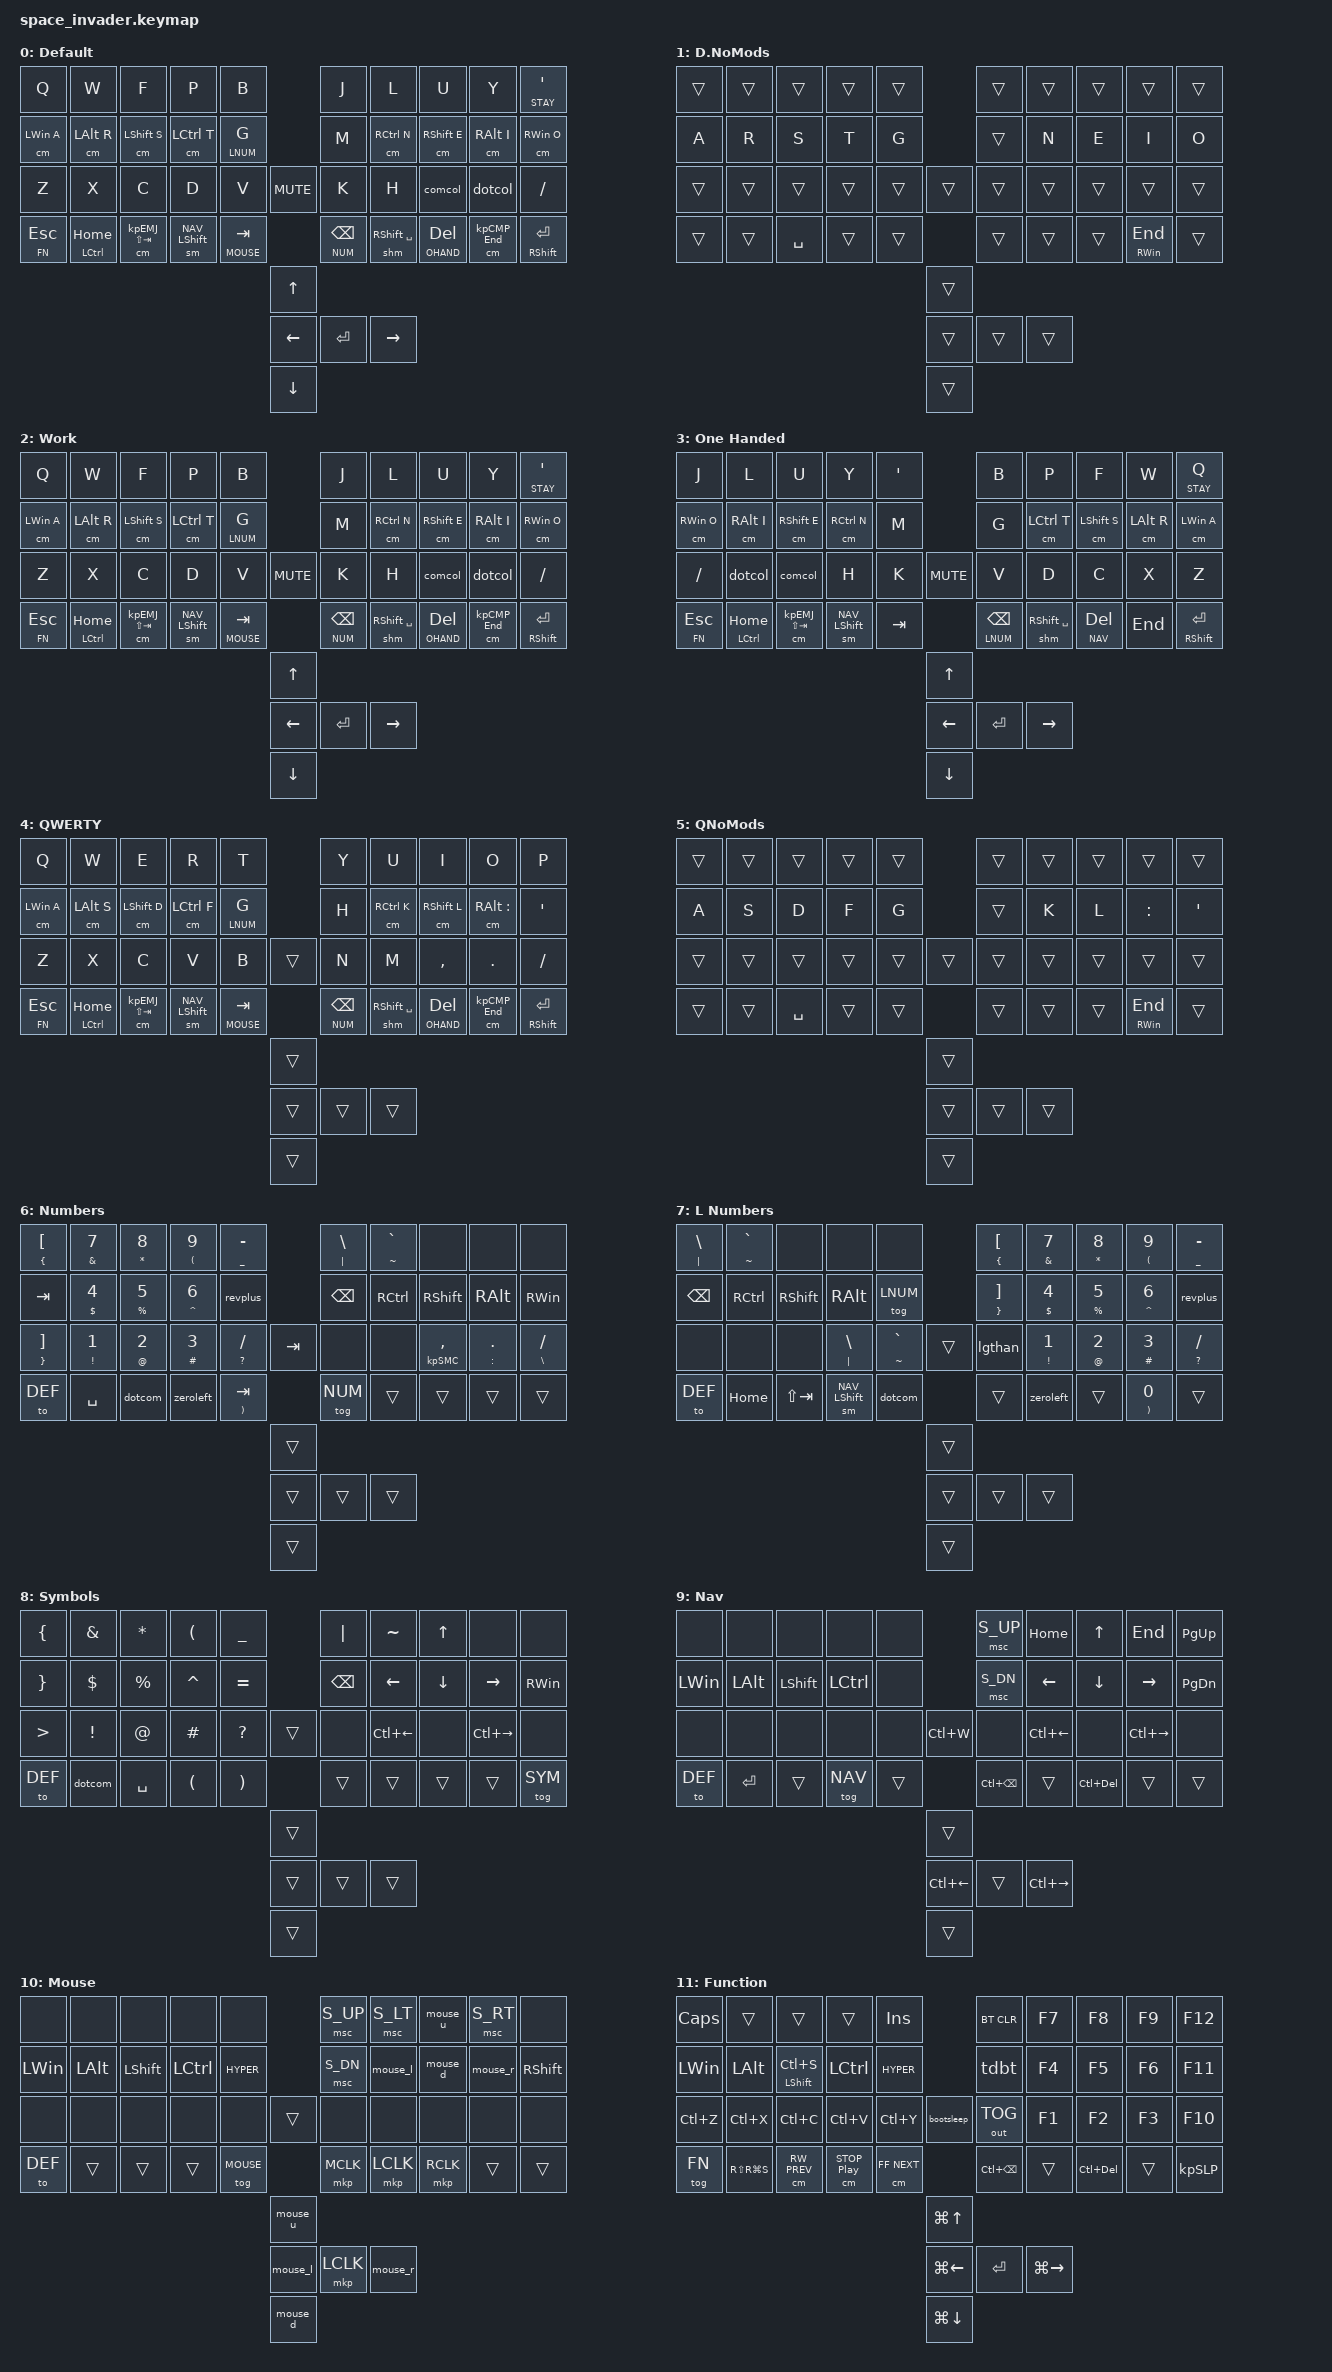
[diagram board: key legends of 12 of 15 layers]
/*
 * Copyright (c) 2021 Tom Butcher
 *
 * SPDX-License-Identifier: MIT
 */

 // standard build command: west build -b adafruit_feather_nrf52840 -- -DSHIELD=space_invader

 /* ********* TO DO *************
	* Once unicode works, create macros that change the layer and send the appropriate F key
	  (for helper image) at the same time.
 */

#include <behaviors.dtsi>
#include <dt-bindings/zmk/keys.h>
#include <dt-bindings/zmk/bt.h>
#include <dt-bindings/zmk/outputs.h>
#include <dt-bindings/zmk/ext_power.h>

// Layer Defs
#define DEF		0
#define DEF_NM	1
#define WORK	2
#define OHAND	3
#define QWERTY	4
#define QWER_NM	5
#define NUM		6
#define LNUM	7
#define SYM		8
#define NAV		9
#define MOUSE	10	
#define FN		11	// Reserved for future use 
#define EMOJI	12	// Reserved for future use
#define CMP		13
#define STAY	14

// F Key subs (use with AHK)
#define KP_PLS	(F18)
#define KP_COM	(F19)
#define KP_SMC	(F20)
#define KP_EMJ	(F21)
#define KP_CMP	(F23)
#define KP_SLP	(LG(LA(LS(LC(APOS)))))

// Other defs
#define xxx		&none	
#define ___		&trans
#define HYPER	(LG(LA(LS(LCTRL))))		  // If I want to send a hypered key, then I might need to make a custom behavior
// #define HYPER	(LG(LA(LS(LCTRL))))   // Maybe try to make a custom mod kp?

#include <../boards/shields/space_invader/key_positions.h>
#include <../boards/shields/space_invader/mouse.dtsi>
#include <../boards/shields/space_invader/helper.h>
#include <../boards/shields/space_invader/behaviors.dtsi>
#include <../boards/shields/space_invader/combos.dtsi>
#include <../boards/shields/space_invader/private.dtsi>

&mt { quick_tap_ms = <200>; };
&lt { quick_tap_ms = <200>; };

/ {
	conditional_layers {
        compatible = "zmk,conditional-layers";
        tri_layer {
            if-layers = <1 4>;
            then-layer = <5>;
        };
    };

	// behaviors {
	// 	tdbt: tap_dance_bluetooth {
	// 	compatible = "zmk,behavior-tap-dance";
    //     #binding-cells = <0>;
	// 	tapping-term-ms = <200>;
	//     bindings = <&bt BT_SEL 0>, <&bt BT_SEL 1>, <&bt BT_SEL 2>, <&bt BT_SEL 3>, <&bt BT_SEL 4>;
	// 	};
	// };

	keymap {
		compatible = "zmk,keymap";

							// -------------------------------------------------TEMPLATE-------------------------------------------------
							// |      |      |      |      |      |                                  |      |      |      |      |      |
							// |      |      |      |      |      |                                  |      |      |      |      |      |
							// |      |      |      |      |      |             |      |             |      |      |      |      |      |
							// |      |------|      |      |      |      |      	          |      |      |      |      |------|      |
							// |----------------------------------|      |      |      |      |      |----------------------------------|
							// ----------------------------------------------------------------------------------------------------------

//------------------------------------------------------------------------------EMPTY TEMPLATE-----------------------------------------------------------------------------
//╭─────────────┬─────────────┬─────────────┬─────────────┬─────────────╮	 		  			    ╭─────────────┬─────────────┬─────────────┬─────────────┬─────────────╮

//├─────────────┼─────────────┼─────────────┼─────────────┼─────────────┤	 					    ├─────────────┼─────────────┼─────────────┼─────────────┼─────────────┤

//├─────────────┼─────────────┼─────────────┼─────────────┼─────────────┤	   ╭─────────────╮      ├─────────────┼─────────────┼─────────────┼─────────────┼─────────────┤

//├─────────────┴───┬─────────┼─────────────┼─────────────┼─────────────┼──────╰──────╮──────╯──────┼─────────────┼─────────────┼─────────────┼─────────┬───┴─────────────┤

//╰─────────────────╯		  ╰─────────────┴─────────────┴─────────────┴─────────────╯─────────────┴─────────────┴─────────────┴─────────────╯	   		╰─────────────────╯
//																		  		 ╭─────────╮

//																	   ╭─────────┼─────────┼─────────╮

//																	   ╰─────────┼─────────┼─────────╯

//																				 ╰─────────╯



		default_layer { 
			display-name = "Default";
			// -------------------------------------------------COLEMAK--------------------------------------------------
			// |  Q   |  W   |  F   |  P   |  B   |                                  |  J   |  L   |  U   |  Y   |  '"  |
			// |  A   |  R   |  S   |  T   |  G   |                                  |  M   |  N   |  E   |  I   |  O   |
			// |  Z   |  X   |  C   |  D   |  V   |             | Mute |             |  K   |  H   |  ,;  |  .:  |  /?  |  // In the future, maybe change back to interobang
			// |  Esc |------| Home |ShftTb|StckSh| Tab  |      	          | Bspc | Space| Del  |  End |------|  Del |  // Although maybe slash is more common than exclamation mark?
			// |----------------------------------|  Up  | Left | Enter| Right| Down |----------------------------------|
			// ----------------------------------------------------------------------------------------------------------
			// ------------------------------------------------HOLD LAYER------------------------------------------------
			// |      |      |      |      |      |                                  |      |      |      |      | Stay |
			// | LWin | LAlt | LShft| LCtrl| LNum |                                  |      | RCtrl| RShft| RAlt | RWin |
			// |      |      |      |      |      |             |      |             |      |      |      |      |      |
			// |  Fn  |------| LCtrl| Emoji| Nav  | Mouse|      	          | Num  | RShft| Cmp  | Sym  |------| Media|
			// |----------------------------------|      |      |      |      |      |----------------------------------|
			// ----------------------------------------------------------------------------------------------------------

			bindings = <
//--------------------------------------------------------------------------------COLEMAK---------------------------------------------------------------------------------
//╭─────────────┬─────────────┬─────────────┬─────────────┬─────────────╮	 		  			    ╭─────────────┬─────────────┬─────────────┬─────────────┬─────────────╮
  	&kp Q		  &kp W			&kp F		  &kp P			&kp B									  &kp J			&kp L		  &kp U			&kp Y		  &lt STAY APOS		// &tdq
//├─────────────┼─────────────┼─────────────┼─────────────┼─────────────┤	 					    ├─────────────┼─────────────┼─────────────┼─────────────┼─────────────┤
  	&cm LWIN A	  &cm LALT R	&cm LSHFT S	  &cm LCTRL T	&lt LNUM G								  &kp M			&cm RCTRL N	  &cm RSHFT E	&cm RALT I	  &cm RWIN O
//├─────────────┼─────────────┼─────────────┼─────────────┼─────────────┤	   ╭─────────────╮      ├─────────────┼─────────────┼─────────────┼─────────────┼─────────────┤
	&kp Z		  &kp X			&kp C		  &kp D			&kp V				  &kp C_MUTE		  &kp K			&kp H		  &comcol		&dotcol		  &kp SLASH
//├─────────────┴───┬─────────┼─────────────┼─────────────┼─────────────┬──────╰──────╮──────╯──────┬─────────────┼─────────────┼─────────────┴─────────┬───┴─────────────┤
	&lt FN ESC			  &mt LCTRL HOME &cm KP_EMJ LS(TAB) &sm NAV LSHFT &lt MOUSE TAB	&lt NUM BSPC &shm RSHFT SPACE &lt OHAND DEL &cm KP_CMP END		  &mt RSHFT RET
//╰─────────────────╯		  ╰─────────────┴─────────────┴─────────────┴─────────────╯─────────────┴─────────────┴─────────────┴─────────────╯	   		╰─────────────────╯
//																		  		 ╭─────────╮
																				  &kp UP
//																	   ╭─────────┼─────────┼─────────╮
																		&kp LEFT  &kp RET	&kp RIGHT
//																	   ╰─────────┼─────────┼─────────╯
																				  &kp DOWN
//																				 ╰─────────╯
			>;

			sensor-bindings = <&scroll>;
		};

		default_no_mods_layer { // Just turns off homerow mods, so no need for the whole keymap diagram
			display-name = "D.NoMods";
			bindings = <___ ___	___ ___ ___ ___ ___ ___ ___ ___ &kp A &kp R &kp S &kp T &kp G ___ &kp N &kp E &kp I &kp O ___ ___ ___ ___ ___ ___ ___ ___ ___ ___ ___
						___ ___ &kp SPACE ___ ___ ___ ___ ___ &mt RWIN END ___ ___ ___ ___ ___ ___>;
			sensor-bindings = <&scroll>;
		};

		work_layer { 
			display-name = "Work";
			bindings = <
//--------------------------------------------------------------------------------COLEMAK---------------------------------------------------------------------------------
//╭─────────────┬─────────────┬─────────────┬─────────────┬─────────────╮	 		  			    ╭─────────────┬─────────────┬─────────────┬─────────────┬─────────────╮
  	&kp Q		  &kp W			&kp F		  &kp P			&kp B									  &kp J			&kp L		  &kp U			&kp Y		  &lt STAY APOS		// &tdq
//├─────────────┼─────────────┼─────────────┼─────────────┼─────────────┤	 					    ├─────────────┼─────────────┼─────────────┼─────────────┼─────────────┤
  	&cm LWIN A	  &cm LALT R	&cm LSHFT S	  &cm LCTRL T	&lt LNUM G								  &kp M			&cm RCTRL N	  &cm RSHFT E	&cm RALT I	  &cm RWIN O
//├─────────────┼─────────────┼─────────────┼─────────────┼─────────────┤	   ╭─────────────╮      ├─────────────┼─────────────┼─────────────┼─────────────┼─────────────┤
	&kp Z		  &kp X			&kp C		  &kp D			&kp V				  &kp C_MUTE		  &kp K			&kp H		  &comcol		&dotcol		  &kp SLASH
//├─────────────┴───┬─────────┼─────────────┼─────────────┼─────────────┬──────╰──────╮──────╯──────┬─────────────┼─────────────┼─────────────┴─────────┬───┴─────────────┤
	&lt FN ESC			  &mt LCTRL HOME &cm KP_EMJ LS(TAB) &sm NAV LSHFT &lt MOUSE TAB	&lt NUM BSPC &shm RSHFT SPACE &lt OHAND DEL &cm KP_CMP END		  &mt RSHFT RET
//╰─────────────────╯		  ╰─────────────┴─────────────┴─────────────┴─────────────╯─────────────┴─────────────┴─────────────┴─────────────╯	   		╰─────────────────╯
//																		  		 ╭─────────╮
																				  &kp UP
//																	   ╭─────────┼─────────┼─────────╮
																		&kp LEFT  &kp RET	&kp RIGHT
//																	   ╰─────────┼─────────┼─────────╯
																				  &kp DOWN
//																				 ╰─────────╯
			>;

			sensor-bindings = <&scroll>;
		};

		one_hand_layer { 
			display-name = "One Handed";
			bindings = <
//--------------------------------------------------------------------------------ONE HAND---------------------------------------------------------------------------------
//╭─────────────┬─────────────┬─────────────┬─────────────┬─────────────╮	 		  			    ╭─────────────┬─────────────┬─────────────┬─────────────┬─────────────╮
  	&kp J		  &kp L			&kp U		  &kp Y			&kp APOS								  &kp B			&kp P		  &kp F			&kp W		  &lt STAY Q
//├─────────────┼─────────────┼─────────────┼─────────────┼─────────────┤	 					    ├─────────────┼─────────────┼─────────────┼─────────────┼─────────────┤
  	&cm RWIN O	  &cm RALT I	&cm RSHFT E	  &cm RCTRL N	&kp M									  &kp G			&cm LCTRL T	  &cm LSHFT S	&cm LALT R	  &cm LWIN A
//├─────────────┼─────────────┼─────────────┼─────────────┼─────────────┤	   ╭─────────────╮      ├─────────────┼─────────────┼─────────────┼─────────────┼─────────────┤
	&kp SLASH	  &dotcol		&comcol		  &kp H		    &kp K				 &kp C_MUTE			  &kp V			&kp D		  &kp C			&kp X		  &kp Z
//├─────────────┴───┬─────────┼─────────────┼─────────────┼─────────────┬──────╰──────╮──────╯──────┬─────────────┼─────────────┼─────────────┴─────────┬───┴─────────────┤
	&lt FN ESC			  &mt LCTRL HOME &cm KP_EMJ LS(TAB) &sm NAV LSHFT &kp TAB		&lt LNUM BSPC &shm RSHFT SPACE &lt NAV DEL &kp END					&mt RSHFT RET
//╰─────────────────╯		  ╰─────────────┴─────────────┴─────────────┴─────────────╯─────────────┴─────────────┴─────────────┴─────────────╯	   		╰─────────────────╯
//																		  		 ╭─────────╮
																				  &kp UP
//																	   ╭─────────┼─────────┼─────────╮
																		&kp LEFT  &kp RET	&kp RIGHT
//																	   ╰─────────┼─────────┼─────────╯
																				  &kp DOWN
//																				 ╰─────────╯
			>;

			sensor-bindings = <&scroll>;
		};

		qwerty_layer {
			display-name = "QWERTY";
			bindings = <
//---------------------------------------------------------------------------------QWERTY---------------------------------------------------------------------------------
//╭─────────────┬─────────────┬─────────────┬─────────────┬─────────────╮	 		  			    ╭─────────────┬─────────────┬─────────────┬─────────────┬─────────────╮
	&kp Q		  &kp W			&kp E		  &kp R			&kp T									  &kp Y			&kp U		  &kp I			&kp O		  &kp P 		// &lt STAY APOS
//├─────────────┼─────────────┼─────────────┼─────────────┼─────────────┤	 					    ├─────────────┼─────────────┼─────────────┼─────────────┼─────────────┤
	&cm LWIN A	  &cm LALT S	&cm LSHFT D	  &cm LCTRL F	&lt LNUM G								  &kp H			&cm RCTRL K	  &cm RSHFT L	&cm RALT COLON &kp APOS
//├─────────────┼─────────────┼─────────────┼─────────────┼─────────────┤	   ╭─────────────╮      ├─────────────┼─────────────┼─────────────┼─────────────┼─────────────┤
	&kp Z		  &kp X			&kp C		  &kp V			&kp B				 ___				  &kp N			&kp M		  &kp COMMA		&kp DOT		  &kp SLASH
//├─────────────┴───┬─────────┼─────────────┼─────────────┼─────────────┬──────╰──────╮──────╯──────┬─────────────┼─────────────┼─────────────┴─────────┬───┴─────────────┤
	&lt FN ESC			  &mt LCTRL HOME &cm KP_EMJ LS(TAB) &sm NAV LSHFT &lt MOUSE TAB	&lt NUM BSPC &shm RSHFT SPACE &lt OHAND DEL &cm KP_CMP END		  &mt RSHFT RET
//╰─────────────────╯		  ╰─────────────┴─────────────┴─────────────┴─────────────╯─────────────┴─────────────┴─────────────┴─────────────╯	   		╰─────────────────╯
//																		  		 ╭─────────╮
																				   ___	
//																	   ╭─────────┼─────────┼─────────╮
																		 ___	   ___		 ___	
//																	   ╰─────────┼─────────┼─────────╯
																				   ___	
//																				 ╰─────────╯
			>;

			sensor-bindings = <&scroll>;
		};

		qwerty_no_mods_layer { // Just turns off homerow mods, so no need for the whole keymap diagram
			display-name = "QNoMods";
			bindings = <___ ___	___ ___ ___ ___ ___ ___ ___ ___ &kp A &kp S &kp D &kp F &kp G ___ &kp K &kp L &kp COLON &kp APOS ___ ___ ___ ___ ___ ___ ___ ___ ___ ___ ___
						___ ___ &kp SPACE ___ ___ ___ ___ ___ &mt RWIN END ___ ___ ___ ___ ___ ___>;
			sensor-bindings = <&scroll>;
		};

		number_layer {
			display-name = "Numbers";
			
			// --------------------------------------------------NUMBER--------------------------------------------------
			// |  [{  |  1!  |  2@  |  3#  |  -_  |                                  |      |  \|  |  `~  |      |      |
			// |  ]}  |  4$  |  5%  |  6^  |  =+  |                                  | BSPC | RCTRL| RSHFT| RALT | RWIN |
			// |  <>  |  7&  |  8*  |  9(  |  \|  |             |      |             |      |      |  ,;  |  .:  |      |
			// | DEF |------| SPACE|  .,  |  0(  |  0)  |      	          |      |      |      |      |------|      |
			// |----------------------------------|      |      |      |      |      |----------------------------------|
			// ----------------------------------------------------------------------------------------------------------

			bindings = < // All numbers use auto-shift for symbols
//---------------------------------------------------------------------------------NUMBERS---------------------------------------------------------------------------------
//╭─────────────┬─────────────┬─────────────┬─────────────┬─────────────╮	 		  				╭─────────────┬─────────────┬─────────────┬─────────────┬─────────────╮
	&as LBRC LBKT &as AMPS N7	&as ASTRK N8  &as LPAR N9 	&as UNDER MINUS							  &as PIPE BSLH &as TILDE GRAVE xxx		  	xxx			  xxx
//├─────────────┼─────────────┼─────────────┼─────────────┼─────────────┤	 						├─────────────┼─────────────┼─────────────┼─────────────┼─────────────┤
	&kp TAB		  &as DLLR N4	&as PRCNT N5  &as CARET N6	&revplus								  &kp BSPC		&kp RCTRL	  &kp RSHFT		&kp RALT	  &kp RWIN
//├─────────────┼─────────────┼─────────────┼─────────────┼─────────────┤	   ╭─────────────╮		├─────────────┼─────────────┼─────────────┼─────────────┼─────────────┤
	&as RBRC RBKT &as EXCL N1	&as AT N2	  &as HASH N3	&as QMARK SLASH	  	 &kp TAB	   		  xxx			xxx		   &as KP_SMC COMMA &as COLON DOT &as BSLH SLASH
//├─────────────┴───┬─────────┼─────────────┼─────────────┼─────────────┬──────╰──────╮──────╯──────┬─────────────┼─────────────┼─────────────┴─────────┬───┴─────────────┤
	&to DEF						&kp SPACE	  &dotcom		&zeroleft	  &as RPAR TAB	&tog NUM	  ___		 	___			  ___						  ___	
//╰─────────────────╯		  ╰─────────────┴─────────────┴─────────────┴─────────────╯─────────────┴─────────────┴─────────────┴─────────────╯	   		╰─────────────────╯
//																		  		 ╭─────────╮
																				   ___	
//																	   ╭─────────┼─────────┼─────────╮
																		 ___	   ___		 ___	
//																	   ╰─────────┼─────────┼─────────╯
																				   ___	
//																				 ╰─────────╯
			>;

			sensor-bindings = <&volume>;
		};


		left_number_layer {
			display-name = "L Numbers";
			
			// -----------------------------------------------LEFT NUMBER------------------------------------------------
			// |  [{  |  1!  |  2@  |  3#  |  -_  |                                  |      |  \|  |  `~  |      |      |
			// |  ]}  |  4$  |  5%  |  6^  |  =+  |                                  | BSPC | RCTRL| RSHFT| RALT | RWIN |
			// |  <>  |  7&  |  8*  |  9(  |  \|  |             |      |             |      |      |  ,;  |  .:  |      |
			// | DEF |------| SPACE|  .,  |  0(  |  0)  |      	          |      |      |      |      |------|      |
			// |----------------------------------|      |      |      |      |      |----------------------------------|
			// ----------------------------------------------------------------------------------------------------------

			bindings = < // All numbers use auto-shift for symbols
//------------------------------------------------------------------------------LEFT NUMBERS-------------------------------------------------------------------------------
//╭─────────────┬─────────────┬─────────────┬─────────────┬─────────────╮	 		  				╭─────────────┬─────────────┬─────────────┬─────────────┬─────────────╮
	&as PIPE BSLH &as TILDE GRAVE xxx		  xxx			xxx										  &as LBRC LBKT &as AMPS N7	  &as ASTRK N8  &as LPAR N9	  &as UNDER MINUS
//├─────────────┼─────────────┼─────────────┼─────────────┼─────────────┤	 						├─────────────┼─────────────┼─────────────┼─────────────┼─────────────┤
	&kp BSPC	  &kp RCTRL	  	&kp RSHFT	  &kp RALT		&tog LNUM								  &as RBRC RBKT &as DLLR N4	  &as PRCNT N5  &as CARET N6  &revplus
//├─────────────┼─────────────┼─────────────┼─────────────┼─────────────┤	   ╭─────────────╮		├─────────────┼─────────────┼─────────────┼─────────────┼─────────────┤
	 xxx		  xxx			xxx			  &as PIPE BSLH &as TILDE GRAVE		  ___				  &lgthan		&as EXCL N1	  &as AT N2		&as HASH N3	  &as QMARK SLASH
//├─────────────┴───┬─────────┼─────────────┼─────────────┼─────────────┬──────╰──────╮──────╯──────┬─────────────┼─────────────┼─────────────┴─────────┬───┴─────────────┤
	&to DEF						&kp HOME	  &kp LS(TAB)	&sm NAV LSHFT &dotcom		___			  &zeroleft	  	___			  &as RPAR N0			  	  ___	
//╰─────────────────╯		  ╰─────────────┴─────────────┴─────────────┴─────────────╯─────────────┴─────────────┴─────────────┴─────────────╯	   		╰─────────────────╯
//																		  		 ╭─────────╮
																				   ___	
//																	   ╭─────────┼─────────┼─────────╮
																		 ___	   ___		 ___	
//																	   ╰─────────┼─────────┼─────────╯
																				   ___	
//																				 ╰─────────╯
			>;

			sensor-bindings = <&volume>;
		};

		symbol_layer {
			display-name = "Symbols";
			bindings = <
//---------------------------------------------------------------------------------SYMBOLS--------------------------------------------------------------------------------
//╭─────────────┬─────────────┬─────────────┬─────────────┬─────────────╮	 		  			    ╭─────────────┬─────────────┬─────────────┬─────────────┬─────────────╮
	&kp LBRC	  &kp AMPS		&kp ASTRK	  &kp LPAR		&kp UNDER					     		  &kp PIPE		&kp TILDE	  &kp UP			xxx			  xxx	
//├─────────────┼─────────────┼─────────────┼─────────────┼─────────────┤	 					    ├─────────────┼─────────────┼─────────────┼─────────────┼─────────────┤
	&kp RBRC	  &kp DLLR		&kp PRCNT	  &kp CARET		&kp EQUAL								  &kp BSPC		&kp LEFT	  &kp DOWN    	&kp RIGHT	  &kp RWIN
//├─────────────┼─────────────┼─────────────┼─────────────┼─────────────┤	   ╭─────────────╮      ├─────────────┼─────────────┼─────────────┼─────────────┼─────────────┤
	&kp GT		  &kp EXCL		&kp AT		  &kp HASH		&kp QMARK		  	 ___				  xxx			&kp LC(LEFT)  xxx			&kp LC(RIGHT)  xxx	
//├─────────────┴───┬─────────┼─────────────┼─────────────┼─────────────┬──────╰──────╮──────╯──────┬─────────────┼─────────────┼─────────────┴─────────┬───┴─────────────┤
	&to DEF						&dotcom		  &kp SPACE		&kp LPAR	  &kp RPAR	    ___			  ___			___			  ___						  &tog SYM
//╰─────────────────╯		  ╰─────────────┴─────────────┴─────────────┴─────────────╯─────────────┴─────────────┴─────────────┴─────────────╯	   		╰─────────────────╯
//																		  		 ╭─────────╮
																				   ___	
//																	   ╭─────────┼─────────┼─────────╮
																		 ___	   ___		 ___	
//																	   ╰─────────┼─────────┼─────────╯
																				   ___	
//																				 ╰─────────╯
			>;

			sensor-bindings = <&volume>;
		};

		navigation_layer {
			display-name = "Nav";
			bindings = <
//-------------------------------------------------------------------------------NAVIGATION-------------------------------------------------------------------------------
//╭─────────────┬─────────────┬─────────────┬─────────────┬─────────────╮	 		  			    ╭─────────────┬─────────────┬─────────────┬─────────────┬─────────────╮
	xxx			  xxx			xxx			  xxx			xxx										  &msc S_UP   	&kp HOME	  &kp UP		&kp END		  &kp PG_UP
//├─────────────┼─────────────┼─────────────┼─────────────┼─────────────┤	 					    ├─────────────┼─────────────┼─────────────┼─────────────┼─────────────┤
  	&kp LWIN	  &kp LALT	 	&kp LSHFT	  &kp LCTRL		xxx										  &msc S_DN   	&kp LEFT	  &kp DOWN    	&kp RIGHT 	  &kp PG_DN
//├─────────────┼─────────────┼─────────────┼─────────────┼─────────────┤	   ╭─────────────╮      ├─────────────┼─────────────┼─────────────┼─────────────┼─────────────┤
	xxx			  xxx			xxx			  xxx			xxx				     &kp LC(W)			  xxx			&kp LC(LEFT)  xxx			&kp LC(RIGHT) xxx	
//├─────────────┴───┬─────────┼─────────────┼─────────────┼─────────────┬──────╰──────╮──────╯──────┬─────────────┼─────────────┼─────────────┴─────────┬───┴─────────────┤
	&to DEF						&kp RET		  ___			&tog NAV	  ___		  	&kp LC(BSPC)  ___			&kp LC(DEL)	  ___						  ___	
//╰─────────────────╯		  ╰─────────────┴─────────────┴─────────────┴─────────────╯─────────────┴─────────────┴─────────────┴─────────────╯	   		╰─────────────────╯
//																		  		 ╭─────────╮
																				   ___	
//																	   ╭─────────┼─────────┼─────────╮
																	&kp LC(LEFT)   ___		 &kp LC(RIGHT)
//																	   ╰─────────┼─────────┼─────────╯
																				   ___	
//																				 ╰─────────╯
			>;

			sensor-bindings = <&tabs>;	// Scroll tabs
		};

		mouse_layer {
			display-name = "Mouse";
			bindings = <
//----------------------------------------------------------------------------------MOUSE---------------------------------------------------------------------------------
//╭─────────────┬─────────────┬─────────────┬─────────────┬─────────────╮	 		  			    ╭─────────────┬─────────────┬─────────────┬─────────────┬─────────────╮
	xxx			  xxx			xxx			  xxx			xxx										  &msc S_UP		&msc S_LT	  &mouse_u		&msc S_RT 	  xxx	
//├─────────────┼─────────────┼─────────────┼─────────────┼─────────────┤	 					    ├─────────────┼─────────────┼─────────────┼─────────────┼─────────────┤
	&kp LWIN	  &kp LALT		&kp LSHFT	  &kp LCTRL		&kp HYPER								  &msc S_DN		&mouse_l	  &mouse_d		&mouse_r	  &kp RSHFT	
//├─────────────┼─────────────┼─────────────┼─────────────┼─────────────┤	   ╭─────────────╮      ├─────────────┼─────────────┼─────────────┼─────────────┼─────────────┤
	xxx			  xxx			xxx			  xxx			xxx					 ___				  xxx			xxx			  xxx			xxx			  xxx
//├─────────────┴───┬─────────┼─────────────┼─────────────┼─────────────┬──────╰──────╮──────╯──────┬─────────────┼─────────────┼─────────────┴─────────┬───┴─────────────┤
	&to DEF						___			  ___			___			  &tog MOUSE	&mkp MCLK	  &mkp LCLK		&mkp RCLK	  ___						  ___	
//╰─────────────────╯		  ╰─────────────┴─────────────┴─────────────┴─────────────╯─────────────┴─────────────┴─────────────┴─────────────╯	   		╰─────────────────╯
//																		  		 ╭─────────╮
																				   &mouse_u	
//																	   ╭─────────┼─────────┼─────────╮
																		 &mouse_l  &mkp LCLK &mouse_r	
//																	   ╰─────────┼─────────┼─────────╯
																				   &mouse_d	
//																				 ╰─────────╯
			>;

			sensor-bindings = <&scroll>;
		};

		function_layer {
			display-name = "Function";
			bindings = <
//--------------------------------------------------------------------------------FUNCTION--------------------------------------------------------------------------------
//╭─────────────┬─────────────┬─────────────┬─────────────┬─────────────╮	 		  			    ╭─────────────┬─────────────┬─────────────┬─────────────┬─────────────╮
	&kp CAPS	  ___	 		___			  ___			&kp INS									  &bt BT_CLR	&kp F7		  &kp F8		&kp F9		  &kp F12
//├─────────────┼─────────────┼─────────────┼─────────────┼─────────────┤	 						├─────────────┼─────────────┼─────────────┼─────────────┼─────────────┤
	&kp LWIN	  &kp LALT	 &mt LSHFT LC(S)  &kp LCTRL		&kp HYPER								  &tdbt			&kp F4		  &kp F5		&kp F6		  &kp F11
//├─────────────┼─────────────┼─────────────┼─────────────┼─────────────┤	   ╭─────────────╮      ├─────────────┼─────────────┼─────────────┼─────────────┼─────────────┤
	&kp LC(Z)	  &kp LC(X)		&kp LC(C)	  &kp LC(V)		&kp LC(Y)   		 &bootsleep			  &out OUT_TOG	&kp F1		  &kp F2		&kp F3		  &kp F10
//├─────────────┴───┬─────────┼─────────────┼─────────────┼─────────────┬──────╰──────╮──────╯──────┬─────────────┼─────────────┼─────────────┴─────────┬───┴─────────────┤
	&tog FN					  &kp RS(RG(S)) &cm C_RW C_PREV &cm C_STOP C_PP &cm C_FF C_NEXT &kp LC(BSPC) ___		&kp LC(DEL)	  ___						  &kp KP_SLP	
//╰─────────────────╯		  ╰─────────────┴─────────────┴─────────────┴─────────────╯─────────────┴─────────────┴─────────────┴─────────────╯	   		╰─────────────────╯
//																		  		 ╭─────────╮
																				   &kp LG(UP)
//																	   ╭─────────┼─────────┼─────────╮
																	  &kp LG(LEFT) &kp RET	 &kp LG(RIGHT)
//																	   ╰─────────┼─────────┼─────────╯
																				   &kp LG(DOWN)
//																				 ╰─────────╯
			>;

			sensor-bindings = <&volume>;
		};

		emoji_layer { // todo: Unicode (including emoji) not yet implemented in ZMK. Maybe try using AHK in the meantime?
			display-name = "Emoji";
			bindings = <
//----------------------------------------------------------------------------------EMOJI---------------------------------------------------------------------------------
//╭─────────────┬─────────────┬─────────────┬─────────────┬─────────────╮	 		  			    ╭─────────────┬─────────────┬─────────────┬─────────────┬─────────────╮
	&kp Q		  ___			___			  ___			___										  ___			___			  ___			___			  ___	
//├─────────────┼─────────────┼─────────────┼─────────────┼─────────────┤	 					    ├─────────────┼─────────────┼─────────────┼─────────────┼─────────────┤
	___			  ___			___			  ___			___										  ___			___			  ___			___			  ___	
//├─────────────┼─────────────┼─────────────┼─────────────┼─────────────┤	   ╭─────────────╮      ├─────────────┼─────────────┼─────────────┼─────────────┼─────────────┤
	___			  ___			___			  ___			___					 ___				  ___			___			  ___			___			  ___	
//├─────────────┴───┬─────────┼─────────────┼─────────────┼─────────────┬──────╰──────╮──────╯──────┬─────────────┼─────────────┼─────────────┴─────────┬───┴─────────────┤
	&to DEF		  				___			  &tog EMOJI	___			  ___			___			  ___			___			  ___						  ___	
//╰─────────────────╯		  ╰─────────────┴─────────────┴─────────────┴─────────────╯─────────────┴─────────────┴─────────────┴─────────────╯	   		╰─────────────────╯
//																		  		 ╭─────────╮
																				   ___	
//																	   ╭─────────┼─────────┼─────────╮
																		 ___	   ___		 ___	
//																	   ╰─────────┼─────────┼─────────╯
																				   ___	
//																				 ╰─────────╯
			>;

			sensor-bindings = <&scroll>;
		};

		compose_layer { // todo: unicode not yet implemented in ZMK. Maybe try using AHK in the meantime?
			display-name = "Compose";
			bindings = <
//---------------------------------------------------------------------------------COMPOSE--------------------------------------------------------------------------------
//╭─────────────┬─────────────┬─────────────┬─────────────┬─────────────╮	 		  			    ╭─────────────┬─────────────┬─────────────┬─────────────┬─────────────╮
	&kp Q		  ___			___			  ___			___										  ___			___			  ___			___			  ___	
//├─────────────┼─────────────┼─────────────┼─────────────┼─────────────┤	 					    ├─────────────┼─────────────┼─────────────┼─────────────┼─────────────┤
	___			  ___			___			  ___			___										  ___			___			  ___			___			  ___	
//├─────────────┼─────────────┼─────────────┼─────────────┼─────────────┤	   ╭─────────────╮      ├─────────────┼─────────────┼─────────────┼─────────────┼─────────────┤
	___			  ___			___			  ___			___					 ___				  ___			___			  ___			___			  ___	
//├─────────────┴───┬─────────┼─────────────┼─────────────┼─────────────┬──────╰──────╮──────╯──────┬─────────────┼─────────────┼─────────────┴─────────┬───┴─────────────┤
	&tog EMOJI	  				___			  ___			___			  ___			___			  ___			___			  &tog CMP					  ___	
//╰─────────────────╯		  ╰─────────────┴─────────────┴─────────────┴─────────────╯─────────────┴─────────────┴─────────────┴─────────────╯	   		╰─────────────────╯
//																		  		 ╭─────────╮
																				   ___	
//																	   ╭─────────┼─────────┼─────────╮
																		 ___	   ___		 ___	
//																	   ╰─────────┼─────────┼─────────╯
																				   ___	
//																				 ╰─────────╯
			>;

			sensor-bindings = <&scroll>;
		};

		stay_layer {	// This layer is for toggling the layers (rather than just holding them on). Can be replaced in the future with double-taps or something
			display-name = "Stay";
			bindings = <
//-------------------------------------------------------------------------------STAY  LAYER-------------------------------------------------------------------------------
//╭─────────────┬─────────────┬─────────────┬─────────────┬─────────────╮	 		  			    ╭─────────────┬─────────────┬─────────────┬─────────────┬─────────────╮
	&kp Q		  ___			___			  ___			___										  ___			___			  ___			___			  ___	
//├─────────────┼─────────────┼─────────────┼─────────────┼─────────────┤	 					    ├─────────────┼─────────────┼─────────────┼─────────────┼─────────────┤
	___			  ___			___			  ___			___										  ___			___			  ___			___			  ___	
//├─────────────┼─────────────┼─────────────┼─────────────┼─────────────┤	   ╭─────────────╮      ├─────────────┼─────────────┼─────────────┼─────────────┼─────────────┤
	___			  ___			___			  ___			___					 ___				  ___			___			  ___			___			  ___	
//├─────────────┴───┬─────────┼─────────────┼─────────────┼─────────────┬──────╰──────╮──────╯──────┬─────────────┼─────────────┼─────────────┴─────────┬───┴─────────────┤
	&tog FN						___			  &tog EMOJI	&tog NAV	  &tog MOUSE	&tog NUM	  &kp CAPS 		&tog CMP	  ___						  &tog SYM
//╰─────────────────╯		  ╰─────────────┴─────────────┴─────────────┴─────────────╯─────────────┴─────────────┴─────────────┴─────────────╯	   		╰─────────────────╯
//																		  		 ╭─────────╮
																				   ___	
//																	   ╭─────────┼─────────┼─────────╮
																		 ___	   ___		 ___	
//																	   ╰─────────┼─────────┼─────────╯
																				   ___	
//																				 ╰─────────╯
			>;

			sensor-bindings = <&scroll>;
		};
	};
};
